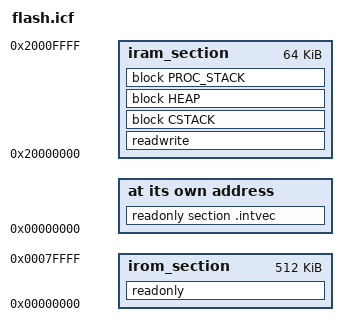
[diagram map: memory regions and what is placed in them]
/****************************************************************************
**
** Copyright (C) 2020 Denis Shienkov <denis.shienkov@gmail.com>
** Contact: https://www.qt.io/licensing/
**
** This file is part of the examples of Qbs.
**
** $QT_BEGIN_LICENSE:BSD$
** Commercial License Usage
** Licensees holding valid commercial Qt licenses may use this file in
** accordance with the commercial license agreement provided with the
** Software or, alternatively, in accordance with the terms contained in
** a written agreement between you and The Qt Company. For licensing terms
** and conditions see https://www.qt.io/terms-conditions. For further
** information use the contact form at https://www.qt.io/contact-us.
**
** BSD License Usage
** Alternatively, you may use this file under the terms of the BSD license
** as follows:
**
** "Redistribution and use in source and binary forms, with or without
** modification, are permitted provided that the following conditions are
** met:
**   * Redistributions of source code must retain the above copyright
**     notice, this list of conditions and the following disclaimer.
**   * Redistributions in binary form must reproduce the above copyright
**     notice, this list of conditions and the following disclaimer in
**     the documentation and/or other materials provided with the
**     distribution.
**   * Neither the name of The Qt Company Ltd nor the names of its
**     contributors may be used to endorse or promote products derived
**     from this software without specific prior written permission.
**
**
** THIS SOFTWARE IS PROVIDED BY THE COPYRIGHT HOLDERS AND CONTRIBUTORS
** "AS IS" AND ANY EXPRESS OR IMPLIED WARRANTIES, INCLUDING, BUT NOT
** LIMITED TO, THE IMPLIED WARRANTIES OF MERCHANTABILITY AND FITNESS FOR
** A PARTICULAR PURPOSE ARE DISCLAIMED. IN NO EVENT SHALL THE COPYRIGHT
** OWNER OR CONTRIBUTORS BE LIABLE FOR ANY DIRECT, INDIRECT, INCIDENTAL,
** SPECIAL, EXEMPLARY, OR CONSEQUENTIAL DAMAGES (INCLUDING, BUT NOT
** LIMITED TO, PROCUREMENT OF SUBSTITUTE GOODS OR SERVICES; LOSS OF USE,
** DATA, OR PROFITS; OR BUSINESS INTERRUPTION) HOWEVER CAUSED AND ON ANY
** THEORY OF LIABILITY, WHETHER IN CONTRACT, STRICT LIABILITY, OR TORT
** (INCLUDING NEGLIGENCE OR OTHERWISE) ARISING IN ANY WAY OUT OF THE USE
** OF THIS SOFTWARE, EVEN IF ADVISED OF THE POSSIBILITY OF SUCH DAMAGE."
**
** $QT_END_LICENSE$
**
****************************************************************************/

define symbol _start_of_intvec_section = 0x00000000;

define symbol _start_of_irom1_section = 0x00000000;
define symbol _end_of_irom1_section   = 0x0007FFFF;
define symbol _start_of_irom2_section = 0x0;
define symbol _end_of_irom2_section   = 0x0;
define symbol _start_of_erom1_section = 0x0;
define symbol _end_of_erom1_section   = 0x0;
define symbol _start_of_erom2_section = 0x0;
define symbol _end_of_erom2_section   = 0x0;
define symbol _start_of_erom3_section = 0x0;
define symbol _end_of_erom3_section   = 0x0;
define symbol _start_of_iram1_section = 0x20000000;
define symbol _end_of_iram1_section   = 0x2000FFFF;
define symbol _start_of_iram2_section = 0x0;
define symbol _end_of_iram2_section   = 0x0;
define symbol _start_of_eram1_section = 0x0;
define symbol _end_of_eram1_section   = 0x0;
define symbol _start_of_eram2_section = 0x0;
define symbol _end_of_eram2_section   = 0x0;
define symbol _start_of_eram3_section = 0x0;
define symbol _end_of_eram3_section   = 0x0;

define symbol _min_stack_size = 0x2000;
define symbol _min_proc_stack_size = 0x0;
define symbol _min_heap_size = 0x2000;

define memory mem with size = 4G;
define region irom_section = mem:[from _start_of_irom1_section to _end_of_irom1_section]
                             | mem:[from _start_of_irom2_section to _end_of_irom2_section];
define region erom_section = mem:[from _start_of_erom1_section to _end_of_erom1_section]
                             | mem:[from _start_of_erom2_section to _end_of_erom2_section]
                             | mem:[from _start_of_erom3_section to _end_of_erom3_section];
define region iram_section = mem:[from _start_of_iram1_section to _end_of_iram1_section]
                             | mem:[from _start_of_iram2_section to _end_of_iram2_section];
define region eram_section = mem:[from _start_of_eram1_section to _end_of_eram1_section]
                             | mem:[from _start_of_eram2_section to _end_of_eram2_section]
                             | mem:[from _start_of_eram3_section to _end_of_eram3_section];


define block CSTACK with alignment = 8, size = _min_stack_size { };
define block PROC_STACK with alignment = 8, size = _min_proc_stack_size { };
define block HEAP with alignment = 8, size = _min_heap_size { };

initialize by copy { readwrite };

place at address mem:_start_of_intvec_section { readonly section .intvec };

place in irom_section { readonly };
place in erom_section { readonly section application_specific_ro };
place in iram_section { readwrite, block CSTACK, block HEAP, block PROC_STACK };
place in eram_section { readwrite section application_specific_rw };
